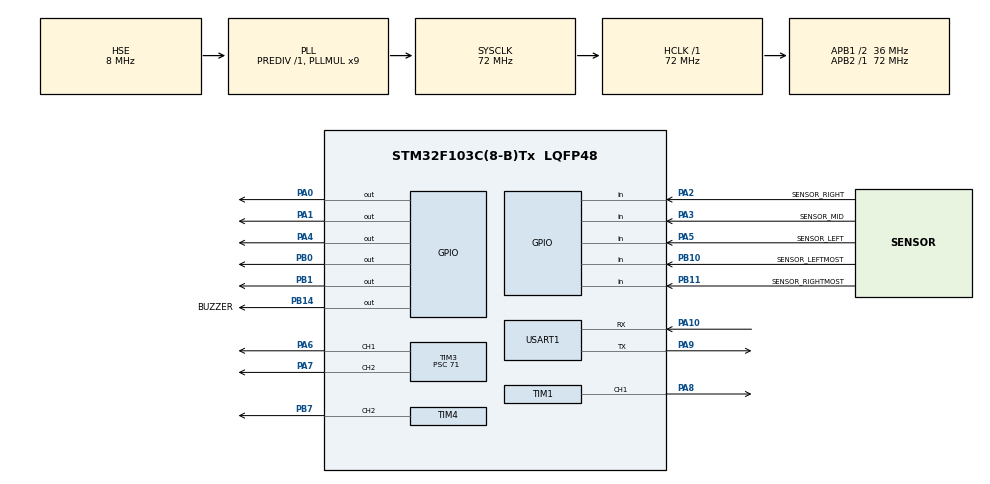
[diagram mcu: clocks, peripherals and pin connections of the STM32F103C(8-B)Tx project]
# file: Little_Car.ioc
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Mcu.Family=STM32F1
Mcu.Name=STM32F103C(8-B)Tx
Mcu.Package=LQFP48
NVIC.PriorityGroup=NVIC_PRIORITYGROUP_4
PA0-WKUP.Signal=GPIO_Output
PA1.Signal=GPIO_Output
PA10.Mode=Asynchronous
PA10.Signal=USART1_RX
PA13.Mode=Serial_Wire
PA13.Signal=SYS_JTMS-SWDIO
PA14.Mode=Serial_Wire
PA14.Signal=SYS_JTCK-SWCLK
PA2.GPIO_Label=SENSOR_RIGHT
PA2.Signal=GPIO_Input
PA3.GPIO_Label=SENSOR_MID
PA3.Signal=GPIO_Input
PA4.Signal=GPIO_Output
PA5.GPIO_Label=SENSOR_LEFT
PA5.Signal=GPIO_Input
PA6.Signal=S_TIM3_CH1
PA7.Signal=S_TIM3_CH2
PA8.Signal=S_TIM1_CH1
PA9.Mode=Asynchronous
PA9.Signal=USART1_TX
PB0.Signal=GPIO_Output
PB1.Signal=GPIO_Output
PB10.GPIO_Label=SENSOR_LEFTMOST
PB10.Signal=GPIO_Input
PB11.GPIO_Label=SENSOR_RIGHTMOST
PB11.Signal=GPIO_Input
PB14.GPIO_Label=BUZZER
PB14.GPIO_ModeDefaultOutputPP=GPIO_MODE_OUTPUT_PP
PB14.GPIO_PuPd=GPIO_PULLUP
PB14.GPIO_Speed=GPIO_SPEED_FREQ_LOW
PB14.PinState=GPIO_PIN_SET
PB14.Signal=GPIO_Output
PB7.Signal=S_TIM4_CH2
PD0-OSC_IN.Mode=HSE-External-Oscillator
PD0-OSC_IN.Signal=RCC_OSC_IN
PD1-OSC_OUT.Mode=HSE-External-Oscillator
PD1-OSC_OUT.Signal=RCC_OSC_OUT
ProjectManager.HeapSize=0x200
ProjectManager.StackSize=0x400
ProjectManager.TargetToolchain=Makefile
RCC.ADCPresc=RCC_ADCPCLK2_DIV6
RCC.AHBFreq_Value=72000000
RCC.APB1CLKDivider=RCC_HCLK_DIV2
RCC.APB1Freq_Value=36000000
RCC.APB1TimFreq_Value=72000000
RCC.APB2Freq_Value=72000000
RCC.APB2TimFreq_Value=72000000
RCC.HCLKFreq_Value=72000000
RCC.PLLMUL=RCC_PLL_MUL9
RCC.PLLSourceVirtual=RCC_PLLSOURCE_HSE
RCC.SYSCLKFreq_VALUE=72000000
RCC.SYSCLKSource=RCC_SYSCLKSOURCE_PLLCLK
RCC.USBFreq_Value=72000000
SH.S_TIM1_CH1.0=TIM1_CH1,PWM Generation1 CH1
SH.S_TIM3_CH1.0=TIM3_CH1,PWM Generation1 CH1
SH.S_TIM3_CH2.0=TIM3_CH2,PWM Generation2 CH2
SH.S_TIM4_CH2.0=TIM4_CH2,PWM Generation2 CH2
TIM1.Channel-PWM\ Generation1\ CH1=TIM_CHANNEL_1
TIM1.Period=1999
TIM1.Prescaler=72
TIM3.AutoReloadPreload=TIM_AUTORELOAD_PRELOAD_ENABLE
TIM3.Channel-PWM\ Generation1\ CH1=TIM_CHANNEL_1
TIM3.Channel-PWM\ Generation2\ CH2=TIM_CHANNEL_2
TIM3.Period=20000 - 1
TIM3.Prescaler=71 
TIM4.Channel-PWM\ Generation2\ CH2=TIM_CHANNEL_2
TIM4.Channel-PWM\ Generation4\ CH4=TIM_CHANNEL_4
USART1.VirtualMode=VM_ASYNC
board=custom

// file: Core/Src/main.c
/* USER CODE BEGIN Header */
/**
  ******************************************************************************
  * @file           : main.c
  * @brief          : Main program body
  ******************************************************************************
  * @attention
  *
  * Copyright (c) 2022 STMicroelectronics.
  * All rights reserved.
  *
  * This software is licensed under terms that can be found in the LICENSE file
  * in the root directory of this software component.
  * If no LICENSE file comes with this software, it is provided AS-IS.
  *
  ******************************************************************************
  */
/* USER CODE END Header */
#include "main.h"

/* USER CODE BEGIN Includes */
#include <stdio.h>
#include "motor.h"
/* USER CODE END Includes */

TIM_HandleTypeDef htim1;
TIM_HandleTypeDef htim3;
TIM_HandleTypeDef htim4;

UART_HandleTypeDef huart1;

void SystemClock_Config(void);
static void MX_GPIO_Init(void);
static void MX_USART1_UART_Init(void);
static void MX_TIM3_Init(void);
static void MX_TIM4_Init(void);
static void MX_TIM1_Init(void);

/* USER CODE BEGIN 0 */
int _write(int file, char *ptr, int len)
{
  HAL_UART_Transmit(&huart1,(uint8_t *)ptr,len,10);
  return len;
}
/* USER CODE END 0 */

int main(void)
{

  /* MCU Configuration--------------------------------------------------------*/

  /* Reset of all peripherals, Initializes the Flash interface and the Systick. */
  HAL_Init();

  /* Configure the system clock */
  SystemClock_Config();

  /* Initialize all configured peripherals */
  MX_GPIO_Init();
  MX_USART1_UART_Init();
  MX_TIM3_Init();
  MX_TIM4_Init();
  MX_TIM1_Init();
  /* USER CODE BEGIN 2 */
  setbuf(stdout, NULL);
  HAL_TIM_PWM_Start(&htim3, TIM_CHANNEL_1);
  HAL_TIM_PWM_Start(&htim3, TIM_CHANNEL_2);
  HAL_TIM_PWM_Start(&htim1, TIM_CHANNEL_1);
  /* USER CODE END 2 */

  /* Infinite loop */
  while (1)
  {

    /* USER CODE BEGIN 3 */
    /* Denote: if the indicator light is off, then the output*/
    /* pin return high level */
    __HAL_TIM_SET_COMPARE(&htim1, TIM_CHANNEL_1, 1999);
    PID_Handle();
    //__HAL_TIM_SET_COMPARE(&htim1, TIM_CHANNEL_1, 750);
    //motor_control(100, 0);
  }
  /* USER CODE END 3 */
}

void SystemClock_Config(void)
{
  RCC_OscInitTypeDef RCC_OscInitStruct = {0};
  RCC_ClkInitTypeDef RCC_ClkInitStruct = {0};

  /** Initializes the RCC Oscillators according to the specified parameters
  * in the RCC_OscInitTypeDef structure.
  */
  RCC_OscInitStruct.OscillatorType = RCC_OSCILLATORTYPE_HSE;
  RCC_OscInitStruct.HSEState = RCC_HSE_ON;
  RCC_OscInitStruct.HSEPredivValue = RCC_HSE_PREDIV_DIV1;
  RCC_OscInitStruct.HSIState = RCC_HSI_ON;
  RCC_OscInitStruct.PLL.PLLState = RCC_PLL_ON;
  RCC_OscInitStruct.PLL.PLLSource = RCC_PLLSOURCE_HSE;
  RCC_OscInitStruct.PLL.PLLMUL = RCC_PLL_MUL9;
  if (HAL_RCC_OscConfig(&RCC_OscInitStruct) != HAL_OK)
  {
    Error_Handler();
  }

  /** Initializes the CPU, AHB and APB buses clocks
  */
  RCC_ClkInitStruct.ClockType = RCC_CLOCKTYPE_HCLK|RCC_CLOCKTYPE_SYSCLK
                              |RCC_CLOCKTYPE_PCLK1|RCC_CLOCKTYPE_PCLK2;
  RCC_ClkInitStruct.SYSCLKSource = RCC_SYSCLKSOURCE_PLLCLK;
  RCC_ClkInitStruct.AHBCLKDivider = RCC_SYSCLK_DIV1;
  RCC_ClkInitStruct.APB1CLKDivider = RCC_HCLK_DIV2;
  RCC_ClkInitStruct.APB2CLKDivider = RCC_HCLK_DIV1;

  if (HAL_RCC_ClockConfig(&RCC_ClkInitStruct, FLASH_LATENCY_2) != HAL_OK)
  {
    Error_Handler();
  }
}

static void MX_TIM1_Init(void)
{

  TIM_MasterConfigTypeDef sMasterConfig = {0};
  TIM_OC_InitTypeDef sConfigOC = {0};
  TIM_BreakDeadTimeConfigTypeDef sBreakDeadTimeConfig = {0};

  htim1.Instance = TIM1;
  htim1.Init.Prescaler = 72;
  htim1.Init.CounterMode = TIM_COUNTERMODE_UP;
  htim1.Init.Period = 1999;
  htim1.Init.ClockDivision = TIM_CLOCKDIVISION_DIV1;
  htim1.Init.RepetitionCounter = 0;
  htim1.Init.AutoReloadPreload = TIM_AUTORELOAD_PRELOAD_DISABLE;
  if (HAL_TIM_PWM_Init(&htim1) != HAL_OK)
  {
    Error_Handler();
  }
  sMasterConfig.MasterOutputTrigger = TIM_TRGO_RESET;
  sMasterConfig.MasterSlaveMode = TIM_MASTERSLAVEMODE_DISABLE;
  if (HAL_TIMEx_MasterConfigSynchronization(&htim1, &sMasterConfig) != HAL_OK)
  {
    Error_Handler();
  }
  sConfigOC.OCMode = TIM_OCMODE_PWM1;
  sConfigOC.Pulse = 0;
  sConfigOC.OCPolarity = TIM_OCPOLARITY_HIGH;
  sConfigOC.OCNPolarity = TIM_OCNPOLARITY_HIGH;
  sConfigOC.OCFastMode = TIM_OCFAST_DISABLE;
  sConfigOC.OCIdleState = TIM_OCIDLESTATE_RESET;
  sConfigOC.OCNIdleState = TIM_OCNIDLESTATE_RESET;
  if (HAL_TIM_PWM_ConfigChannel(&htim1, &sConfigOC, TIM_CHANNEL_1) != HAL_OK)
  {
    Error_Handler();
  }
  sBreakDeadTimeConfig.OffStateRunMode = TIM_OSSR_DISABLE;
  sBreakDeadTimeConfig.OffStateIDLEMode = TIM_OSSI_DISABLE;
  sBreakDeadTimeConfig.LockLevel = TIM_LOCKLEVEL_OFF;
  sBreakDeadTimeConfig.DeadTime = 0;
  sBreakDeadTimeConfig.BreakState = TIM_BREAK_DISABLE;
  sBreakDeadTimeConfig.BreakPolarity = TIM_BREAKPOLARITY_HIGH;
  sBreakDeadTimeConfig.AutomaticOutput = TIM_AUTOMATICOUTPUT_DISABLE;
  if (HAL_TIMEx_ConfigBreakDeadTime(&htim1, &sBreakDeadTimeConfig) != HAL_OK)
  {
    Error_Handler();
  }
  HAL_TIM_MspPostInit(&htim1);

}

static void MX_TIM3_Init(void)
{

  TIM_MasterConfigTypeDef sMasterConfig = {0};
  TIM_OC_InitTypeDef sConfigOC = {0};

  htim3.Instance = TIM3;
  htim3.Init.Prescaler = 71 ;
  htim3.Init.CounterMode = TIM_COUNTERMODE_UP;
  htim3.Init.Period = 20000 - 1;
  htim3.Init.ClockDivision = TIM_CLOCKDIVISION_DIV1;
  htim3.Init.AutoReloadPreload = TIM_AUTORELOAD_PRELOAD_ENABLE;
  if (HAL_TIM_PWM_Init(&htim3) != HAL_OK)
  {
    Error_Handler();
  }
  sMasterConfig.MasterOutputTrigger = TIM_TRGO_RESET;
  sMasterConfig.MasterSlaveMode = TIM_MASTERSLAVEMODE_DISABLE;
  if (HAL_TIMEx_MasterConfigSynchronization(&htim3, &sMasterConfig) != HAL_OK)
  {
    Error_Handler();
  }
  sConfigOC.OCMode = TIM_OCMODE_PWM1;
  sConfigOC.Pulse = 0;
  sConfigOC.OCPolarity = TIM_OCPOLARITY_HIGH;
  sConfigOC.OCFastMode = TIM_OCFAST_DISABLE;
  if (HAL_TIM_PWM_ConfigChannel(&htim3, &sConfigOC, TIM_CHANNEL_1) != HAL_OK)
  {
    Error_Handler();
  }
  if (HAL_TIM_PWM_ConfigChannel(&htim3, &sConfigOC, TIM_CHANNEL_2) != HAL_OK)
  {
    Error_Handler();
  }
  HAL_TIM_MspPostInit(&htim3);

}

static void MX_TIM4_Init(void)
{

  TIM_MasterConfigTypeDef sMasterConfig = {0};
  TIM_OC_InitTypeDef sConfigOC = {0};

  htim4.Instance = TIM4;
  htim4.Init.Prescaler = 0;
  htim4.Init.CounterMode = TIM_COUNTERMODE_UP;
  htim4.Init.Period = 65535;
  htim4.Init.ClockDivision = TIM_CLOCKDIVISION_DIV1;
  htim4.Init.AutoReloadPreload = TIM_AUTORELOAD_PRELOAD_DISABLE;
  if (HAL_TIM_PWM_Init(&htim4) != HAL_OK)
  {
    Error_Handler();
  }
  sMasterConfig.MasterOutputTrigger = TIM_TRGO_RESET;
  sMasterConfig.MasterSlaveMode = TIM_MASTERSLAVEMODE_DISABLE;
  if (HAL_TIMEx_MasterConfigSynchronization(&htim4, &sMasterConfig) != HAL_OK)
  {
    Error_Handler();
  }
  sConfigOC.OCMode = TIM_OCMODE_PWM1;
  sConfigOC.Pulse = 0;
  sConfigOC.OCPolarity = TIM_OCPOLARITY_HIGH;
  sConfigOC.OCFastMode = TIM_OCFAST_DISABLE;
  if (HAL_TIM_PWM_ConfigChannel(&htim4, &sConfigOC, TIM_CHANNEL_2) != HAL_OK)
  {
    Error_Handler();
  }
  HAL_TIM_MspPostInit(&htim4);

}

static void MX_USART1_UART_Init(void)
{

  huart1.Instance = USART1;
  huart1.Init.BaudRate = 115200;
  huart1.Init.WordLength = UART_WORDLENGTH_8B;
  huart1.Init.StopBits = UART_STOPBITS_1;
  huart1.Init.Parity = UART_PARITY_NONE;
  huart1.Init.Mode = UART_MODE_TX_RX;
  huart1.Init.HwFlowCtl = UART_HWCONTROL_NONE;
  huart1.Init.OverSampling = UART_OVERSAMPLING_16;
  if (HAL_UART_Init(&huart1) != HAL_OK)
  {
    Error_Handler();
  }

}

static void MX_GPIO_Init(void)
{
  GPIO_InitTypeDef GPIO_InitStruct = {0};

  /* GPIO Ports Clock Enable */
  __HAL_RCC_GPIOD_CLK_ENABLE();
  __HAL_RCC_GPIOA_CLK_ENABLE();
  __HAL_RCC_GPIOB_CLK_ENABLE();

  /*Configure GPIO pin Output Level */
  HAL_GPIO_WritePin(GPIOA, GPIO_PIN_0|GPIO_PIN_1|GPIO_PIN_4, GPIO_PIN_RESET);

  /*Configure GPIO pin Output Level */
  HAL_GPIO_WritePin(GPIOB, GPIO_PIN_0|GPIO_PIN_1, GPIO_PIN_RESET);

  /*Configure GPIO pin Output Level */
  HAL_GPIO_WritePin(BUZZER_GPIO_Port, BUZZER_Pin, GPIO_PIN_SET);

  /*Configure GPIO pins : PA0 PA1 PA4 */
  GPIO_InitStruct.Pin = GPIO_PIN_0|GPIO_PIN_1|GPIO_PIN_4;
  GPIO_InitStruct.Mode = GPIO_MODE_OUTPUT_PP;
  GPIO_InitStruct.Pull = GPIO_NOPULL;
  GPIO_InitStruct.Speed = GPIO_SPEED_FREQ_LOW;
  HAL_GPIO_Init(GPIOA, &GPIO_InitStruct);

  /*Configure GPIO pins : SENSOR_RIGHT_Pin SENSOR_MID_Pin SENSOR_LEFT_Pin */
  GPIO_InitStruct.Pin = SENSOR_RIGHT_Pin|SENSOR_MID_Pin|SENSOR_LEFT_Pin;
  GPIO_InitStruct.Mode = GPIO_MODE_INPUT;
  GPIO_InitStruct.Pull = GPIO_NOPULL;
  HAL_GPIO_Init(GPIOA, &GPIO_InitStruct);

  /*Configure GPIO pins : PB0 PB1 */
  GPIO_InitStruct.Pin = GPIO_PIN_0|GPIO_PIN_1;
  GPIO_InitStruct.Mode = GPIO_MODE_OUTPUT_PP;
  GPIO_InitStruct.Pull = GPIO_NOPULL;
  GPIO_InitStruct.Speed = GPIO_SPEED_FREQ_LOW;
  HAL_GPIO_Init(GPIOB, &GPIO_InitStruct);

  /*Configure GPIO pins : SENSOR_LEFTMOST_Pin SENSOR_RIGHTMOST_Pin */
  GPIO_InitStruct.Pin = SENSOR_LEFTMOST_Pin|SENSOR_RIGHTMOST_Pin;
  GPIO_InitStruct.Mode = GPIO_MODE_INPUT;
  GPIO_InitStruct.Pull = GPIO_NOPULL;
  HAL_GPIO_Init(GPIOB, &GPIO_InitStruct);

  /*Configure GPIO pin : BUZZER_Pin */
  GPIO_InitStruct.Pin = BUZZER_Pin;
  GPIO_InitStruct.Mode = GPIO_MODE_OUTPUT_PP;
  GPIO_InitStruct.Pull = GPIO_PULLUP;
  GPIO_InitStruct.Speed = GPIO_SPEED_FREQ_LOW;
  HAL_GPIO_Init(BUZZER_GPIO_Port, &GPIO_InitStruct);

}

void Error_Handler(void)
{
  __disable_irq();
  while (1)
  {
  }
}
